AUTOSAR XML (schema 00046)
package /Appl_ComShell/DataTypeMappingSets
  data type mapping set Appl_ComShell_DTMap
    data-type-maps:
      application-data-type=CarTiGlb_2, implementation-data-type=uint32
      application-data-type=Len31_2, implementation-data-type=uint32
      application-data-type=WhlMotSysModStsTyp1_2, implementation-data-type=uint8
      application-data-type=HvTq1_2, implementation-data-type=uint16
      application-data-type=CooltTHiResl_2, implementation-data-type=uint16
      application-data-type=CooltFlow2_2, implementation-data-type=uint16
      application-data-type=N1_2, implementation-data-type=uint16
      application-data-type=PrpsnPwrLimMax_2, implementation-data-type=uint16
      application-data-type=PrpsnPwrLimMin_2, implementation-data-type=uint16
      application-data-type=WhlMotSysModStsTyp2_2, implementation-data-type=uint8
      application-data-type=IsgSpdWSgnTyp_2, implementation-data-type=sint16
      application-data-type=HvU1_2, implementation-data-type=uint16
      application-data-type=T3_2, implementation-data-type=uint8
      application-data-type=HvT1_3, implementation-data-type=uint8
      application-data-type=Ampr1_1, implementation-data-type=uint16
      application-data-type=UInt16_2, implementation-data-type=uint16
      application-data-type=HvCoolg1_2, implementation-data-type=uint8
      application-data-type=OnOff1_2, implementation-data-type=uint8
      application-data-type=OnBdChrgrHndlSts_2, implementation-data-type=uint8
      application-data-type=GearLvrIndcn2_2, implementation-data-type=uint8
      application-data-type=Perc7_2, implementation-data-type=uint16
      application-data-type=ImobSts_2, implementation-data-type=uint8
      application-data-type=OnBdChrgrHndlSts1_2, implementation-data-type=uint8
      application-data-type=FltIndcn_1, implementation-data-type=uint8
      application-data-type=FltLvl_1, implementation-data-type=uint8
      application-data-type=PLockParkRequest_1, implementation-data-type=uint8
      application-data-type=ParkSts_1, implementation-data-type=uint8
      application-data-type=UInt4_2, implementation-data-type=uint8
      application-data-type=FrntHeatModEnad_1, implementation-data-type=uint8
      application-data-type=IsgHeatPwr_1, implementation-data-type=uint8
      application-data-type=CooltFlowForDtElec1_2, implementation-data-type=uint16
      application-data-type=WhlMotSysActvDampgModCodSts_2, implementation-data-type=uint8
      application-data-type=WhlMotSysHeatFdBck_1, implementation-data-type=uint8
package /Appl_ComShell/ComponentTypes
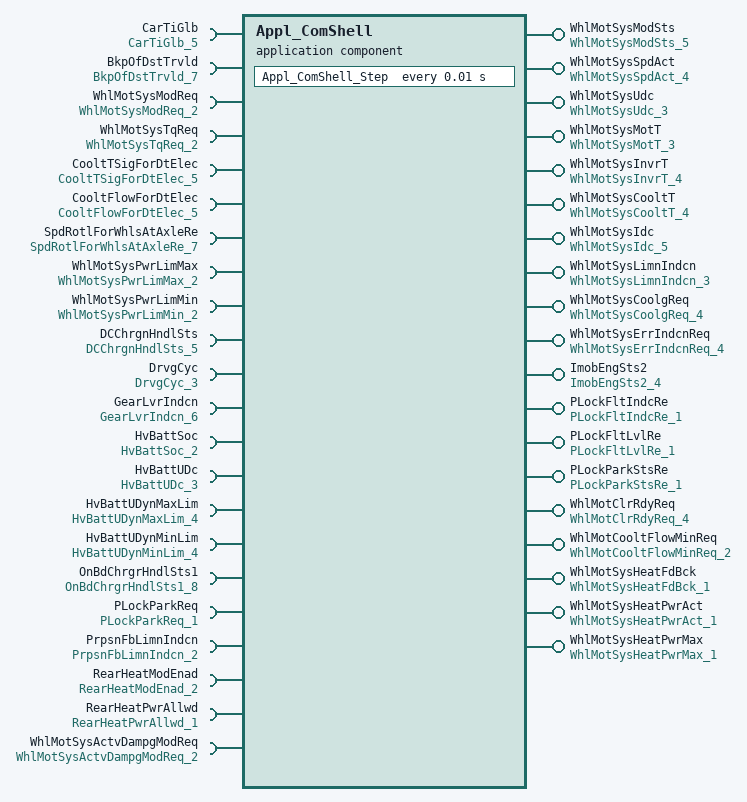
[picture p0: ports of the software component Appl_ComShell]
  application sw component type Appl_ComShell
    9 x require port:
      CarTiGlb: nonqueued-receiver-com-spec{data-element=CarTiGlb, init-value=0}, required-interface=CarTiGlb_5
      BkpOfDstTrvld: nonqueued-receiver-com-spec{data-element=BkpOfDstTrvld, init-value=0}, required-interface=BkpOfDstTrvld_7
      WhlMotSysModReq: nonqueued-receiver-com-spec{data-element=WhlMotSysModReq, init-value=0}, required-interface=WhlMotSysModReq_2
      WhlMotSysTqReq: nonqueued-receiver-com-spec{data-element=WhlMotSysTqReq, init-value=0}, required-interface=WhlMotSysTqReq_2
      CooltTSigForDtElec: nonqueued-receiver-com-spec{data-element=CooltTSigForDtElec, init-value=0}, required-interface=CooltTSigForDtElec_5
      CooltFlowForDtElec: nonqueued-receiver-com-spec{data-element=CooltFlowForDtElec, init-value=0}, required-interface=CooltFlowForDtElec_5
      SpdRotlForWhlsAtAxleRe: nonqueued-receiver-com-spec{data-element=SpdRotlForWhlsAtAxleRe, init-value=0}, required-interface=SpdRotlForWhlsAtAxleRe_7
      WhlMotSysPwrLimMax: nonqueued-receiver-com-spec{data-element=WhlMotSysPwrLimMax, init-value=0}, required-interface=WhlMotSysPwrLimMax_2
      WhlMotSysPwrLimMin: nonqueued-receiver-com-spec{data-element=WhlMotSysPwrLimMin, init-value=0}, required-interface=WhlMotSysPwrLimMin_2
    10 x provide port:
      WhlMotSysModSts: nonqueued-sender-com-spec{data-element=WhlMotSysModSts, init-value=0}, provided-interface=WhlMotSysModSts_5
      WhlMotSysSpdAct: nonqueued-sender-com-spec{data-element=WhlMotSysSpdAct, init-value=0}, provided-interface=WhlMotSysSpdAct_4
      WhlMotSysUdc: nonqueued-sender-com-spec{data-element=WhlMotSysUdc, init-value=0}, provided-interface=WhlMotSysUdc_3
      WhlMotSysMotT: nonqueued-sender-com-spec{data-element=WhlMotSysMotT, init-value=0}, provided-interface=WhlMotSysMotT_3
      WhlMotSysInvrT: nonqueued-sender-com-spec{data-element=WhlMotSysInvrT, init-value=0}, provided-interface=WhlMotSysInvrT_4
      WhlMotSysCooltT: nonqueued-sender-com-spec{data-element=WhlMotSysCooltT, init-value=0}, provided-interface=WhlMotSysCooltT_4
      WhlMotSysIdc: nonqueued-sender-com-spec{data-element=WhlMotSysIdc, init-value=0}, provided-interface=WhlMotSysIdc_5
      WhlMotSysLimnIndcn: nonqueued-sender-com-spec{data-element=WhlMotSysLimnIndcn, init-value=0}, provided-interface=WhlMotSysLimnIndcn_3
      WhlMotSysCoolgReq: nonqueued-sender-com-spec{data-element=WhlMotSysCoolgReq, init-value=0}, provided-interface=WhlMotSysCoolgReq_4
      WhlMotSysErrIndcnReq: nonqueued-sender-com-spec{data-element=WhlMotSysErrIndcnReq, init-value=0}, provided-interface=WhlMotSysErrIndcnReq_4
    7 x require port:
      DCChrgnHndlSts: nonqueued-receiver-com-spec{data-element=DCChrgnHndlSts, init-value=0}, required-interface=DCChrgnHndlSts_5
      DrvgCyc: nonqueued-receiver-com-spec{data-element=DrvgCyc, init-value=0}, required-interface=DrvgCyc_3
      GearLvrIndcn: nonqueued-receiver-com-spec{data-element=GearLvrIndcn, init-value=0}, required-interface=GearLvrIndcn_6
      HvBattSoc: nonqueued-receiver-com-spec{data-element=HvBattSoc, init-value=0}, required-interface=HvBattSoc_2
      HvBattUDc: nonqueued-receiver-com-spec{data-element=HvBattUDc, init-value=0}, required-interface=HvBattUDc_3
      HvBattUDynMaxLim: nonqueued-receiver-com-spec{data-element=HvBattUDynMaxLim, init-value=0}, required-interface=HvBattUDynMaxLim_4
      HvBattUDynMinLim: nonqueued-receiver-com-spec{data-element=HvBattUDynMinLim, init-value=0}, required-interface=HvBattUDynMinLim_4
    provide port ImobEngSts2: nonqueued-sender-com-spec{data-element=ImobEngSts2, init-value=0}, provided-interface=ImobEngSts2_4
    require port OnBdChrgrHndlSts1: nonqueued-receiver-com-spec{data-element=OnBdChrgrHndlSts1, init-value=0}, required-interface=OnBdChrgrHndlSts1_8
    provide port PLockFltIndcRe: nonqueued-sender-com-spec{data-element=PLockFltIndcRe, init-value=0}, provided-interface=PLockFltIndcRe_1
    provide port PLockFltLvlRe: nonqueued-sender-com-spec{data-element=PLockFltLvlRe, init-value=0}, provided-interface=PLockFltLvlRe_1
    require port PLockParkReq: nonqueued-receiver-com-spec{data-element=PLockParkReq, init-value=0}, required-interface=PLockParkReq_1
    provide port PLockParkStsRe: nonqueued-sender-com-spec{data-element=PLockParkStsRe, init-value=0}, provided-interface=PLockParkStsRe_1
    require port PrpsnFbLimnIndcn: nonqueued-receiver-com-spec{data-element=PrpsnFbLimnIndcn, init-value=0}, required-interface=PrpsnFbLimnIndcn_2
    require port RearHeatModEnad: nonqueued-receiver-com-spec{data-element=RearHeatModEnad, init-value=0}, required-interface=RearHeatModEnad_2
    require port RearHeatPwrAllwd: nonqueued-receiver-com-spec{data-element=RearHeatPwrAllwd, init-value=0}, required-interface=RearHeatPwrAllwd_1
    provide port WhlMotClrRdyReq: nonqueued-sender-com-spec{data-element=WhlMotClrRdyReq, init-value=0}, provided-interface=WhlMotClrRdyReq_4
    provide port WhlMotCooltFlowMinReq: nonqueued-sender-com-spec{data-element=WhlMotCooltFlowMinReq, init-value=0}, provided-interface=WhlMotCooltFlowMinReq_2
    require port WhlMotSysActvDampgModReq: nonqueued-receiver-com-spec{data-element=WhlMotSysActvDampgModReq, init-value=0}, required-interface=WhlMotSysActvDampgModReq_2
    provide port WhlMotSysHeatFdBck: nonqueued-sender-com-spec{data-element=WhlMotSysHeatFdBck, init-value=0}, provided-interface=WhlMotSysHeatFdBck_1
    provide port WhlMotSysHeatPwrAct: nonqueued-sender-com-spec{data-element=WhlMotSysHeatPwrAct, init-value=0}, provided-interface=WhlMotSysHeatPwrAct_1
    provide port WhlMotSysHeatPwrMax: nonqueued-sender-com-spec{data-element=WhlMotSysHeatPwrMax, init-value=0}, provided-interface=WhlMotSysHeatPwrMax_1
    behavior Appl_ComShellInternalBehavior: data-type-mapping=Appl_ComShell_DTMap, handle-termination-and-restart=NO-SUPPORT
      timing event RE_Appl_ComShell_Step: start-on-event=Appl_ComShell_Step, period=0.01
      runnable Appl_ComShell_Step
        data-receive-point-by-arguments:
          22 x access:
            DRA_CarTiGlb: accessed-variable=CarTiGlb.CarTiGlb
            DRA_BkpOfDstTrvld: accessed-variable=BkpOfDstTrvld.BkpOfDstTrvld
            DRA_WhlMotSysModReq: accessed-variable=WhlMotSysModReq.WhlMotSysModReq
            DRA_WhlMotSysTqReq: accessed-variable=WhlMotSysTqReq.WhlMotSysTqReq
            DRA_CooltTSigForDtElec: accessed-variable=CooltTSigForDtElec.CooltTSigForDtElec
            DRA_CooltFlowForDtElec: accessed-variable=CooltFlowForDtElec.CooltFlowForDtElec
            DRA_SpdRotlForWhlsAtAxleRe: accessed-variable=SpdRotlForWhlsAtAxleRe.SpdRotlForWhlsAtAxleRe
            DRA_WhlMotSysPwrLimMax: accessed-variable=WhlMotSysPwrLimMax.WhlMotSysPwrLimMax
            DRA_WhlMotSysPwrLimMin: accessed-variable=WhlMotSysPwrLimMin.WhlMotSysPwrLimMin
            DRA_DCChrgnHndlSts: accessed-variable=DCChrgnHndlSts.DCChrgnHndlSts
            DRA_DrvgCyc: accessed-variable=DrvgCyc.DrvgCyc
            DRA_GearLvrIndcn: accessed-variable=GearLvrIndcn.GearLvrIndcn
            DRA_HvBattSoc: accessed-variable=HvBattSoc.HvBattSoc
            DRA_HvBattUDc: accessed-variable=HvBattUDc.HvBattUDc
            DRA_HvBattUDynMaxLim: accessed-variable=HvBattUDynMaxLim.HvBattUDynMaxLim
            DRA_HvBattUDynMinLim: accessed-variable=HvBattUDynMinLim.HvBattUDynMinLim
            DRA_OnBdChrgrHndlSts1: accessed-variable=OnBdChrgrHndlSts1.OnBdChrgrHndlSts1
            DRA_PLockParkReq: accessed-variable=PLockParkReq.PLockParkReq
            DRA_PrpsnFbLimnIndcn: accessed-variable=PrpsnFbLimnIndcn.PrpsnFbLimnIndcn
            DRA_RearHeatModEnad: accessed-variable=RearHeatModEnad.RearHeatModEnad
            DRA_RearHeatPwrAllwd: accessed-variable=RearHeatPwrAllwd.RearHeatPwrAllwd
            DRA_WhlMotSysActvDampgModReq: accessed-variable=WhlMotSysActvDampgModReq.WhlMotSysActvDampgModReq
        data-send-points:
          19 x access:
            DSP_WhlMotSysModSts: accessed-variable=WhlMotSysModSts.WhlMotSysModSts
            DSP_WhlMotSysSpdAct: accessed-variable=WhlMotSysSpdAct.WhlMotSysSpdAct
            DSP_WhlMotSysUdc: accessed-variable=WhlMotSysUdc.WhlMotSysUdc
            DSP_WhlMotSysMotT: accessed-variable=WhlMotSysMotT.WhlMotSysMotT
            DSP_WhlMotSysInvrT: accessed-variable=WhlMotSysInvrT.WhlMotSysInvrT
            DSP_WhlMotSysCooltT: accessed-variable=WhlMotSysCooltT.WhlMotSysCooltT
            DSP_WhlMotSysIdc: accessed-variable=WhlMotSysIdc.WhlMotSysIdc
            DSP_WhlMotSysLimnIndcn: accessed-variable=WhlMotSysLimnIndcn.WhlMotSysLimnIndcn
            DSP_WhlMotSysCoolgReq: accessed-variable=WhlMotSysCoolgReq.WhlMotSysCoolgReq
            DSP_WhlMotSysErrIndcnReq: accessed-variable=WhlMotSysErrIndcnReq.WhlMotSysErrIndcnReq
            DSP_ImobEngSts2: accessed-variable=ImobEngSts2.ImobEngSts2
            DSP_PLockFltIndcRe: accessed-variable=PLockFltIndcRe.PLockFltIndcRe
            DSP_PLockFltLvlRe: accessed-variable=PLockFltLvlRe.PLockFltLvlRe
            DSP_PLockParkStsRe: accessed-variable=PLockParkStsRe.PLockParkStsRe
            DSP_WhlMotClrRdyReq: accessed-variable=WhlMotClrRdyReq.WhlMotClrRdyReq
            DSP_WhlMotCooltFlowMinReq: accessed-variable=WhlMotCooltFlowMinReq.WhlMotCooltFlowMinReq
            DSP_WhlMotSysHeatFdBck: accessed-variable=WhlMotSysHeatFdBck.WhlMotSysHeatFdBck
            DSP_WhlMotSysHeatPwrAct: accessed-variable=WhlMotSysHeatPwrAct.WhlMotSysHeatPwrAct
            DSP_WhlMotSysHeatPwrMax: accessed-variable=WhlMotSysHeatPwrMax.WhlMotSysHeatPwrMax
  swc implementation Appl_ComShellImplementation: programming-language=C, sw-version=0.5.0, behavior=Appl_ComShellInternalBehavior
